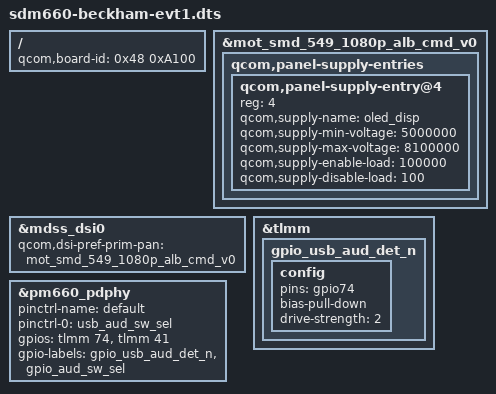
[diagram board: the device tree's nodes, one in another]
/* Copyright (c) 2016, Motorola Mobility Inc. All rights reserved.
 *
 * This program is free software; you can redistribute it and/or modify
 * it under the terms of the GNU General Public License version 2 and
 * only version 2 as published by the Free Software Foundation.
 *
 * This program is distributed in the hope that it will be useful,
 * but WITHOUT ANY WARRANTY; without even the implied warranty of
 * MERCHANTABILITY or FITNESS FOR A PARTICULAR PURPOSE.  See the
 * GNU General Public License for more details.
 */


/dts-v1/;

#include "sdm660.dtsi"
#include "sdm660-beckham.dtsi"
#include "dsi-panel-mot-smd-549-1080p-alb-cmd.dtsi"

/ {
	qcom,board-id = <0x48 0xA100>;
};

&mot_smd_549_1080p_alb_cmd_v0 {
	qcom,panel-supply-entries {
			qcom,panel-supply-entry@4 {
				reg = <4>;
				qcom,supply-name = "oled_disp";
				qcom,supply-min-voltage = <5000000>;
				qcom,supply-max-voltage = <8100000>;
				qcom,supply-enable-load = <100000>;
				qcom,supply-disable-load = <100>;
			};
	};
};

&mdss_dsi0 {
	qcom,dsi-pref-prim-pan = <&mot_smd_549_1080p_alb_cmd_v0>;
};

&tlmm {
	gpio_usb_aud_det_n: gpio_usb_aud_det_n {
		config {
			pins = "gpio74";
			bias-pull-down;
			drive-strength = <2>;
		};
	};
};

&pm660_pdphy {
	pinctrl-name = "default";
	pinctrl-0 = <&usb_aud_sw_sel>;

	gpios = <&tlmm 74 0>,  /* USB_AUD_DET_N, output-high */
		<&tlmm 41 0>;  /* USB_AUD_SW_SEL, output-low */

	gpio-labels = "gpio_usb_aud_det_n",
		"gpio_aud_sw_sel";
};
